VERSION ""

NS_ :

BS_:

BU_:

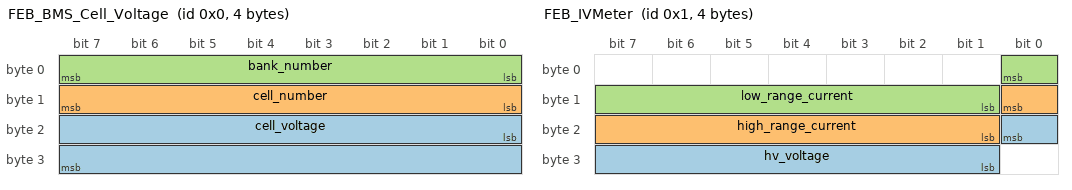
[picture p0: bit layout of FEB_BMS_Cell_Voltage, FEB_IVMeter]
BO_ 0 FEB_BMS_Cell_Voltage: 4 Vector__XXX
 SG_ cell_voltage : 16|16@1+ (0.001,0) [0|0] "mV" Vector__XXX
 SG_ cell_number : 8|8@1+ (1,0) [0|0] "" Vector__XXX
 SG_ bank_number : 0|8@1+ (1,0) [0|0] "" Vector__XXX

BO_ 1 FEB_IVMeter: 4 Vector__XXX
 SG_ hv_voltage : 16|8@0+ (1,0) [0|0] "V" Vector__XXX
 SG_ high_range_current : 8|8@0+ (1,0) [0|0] "" Vector__XXX
 SG_ low_range_current : 0|8@0+ (1,0) [0|0] "" Vector__XXX

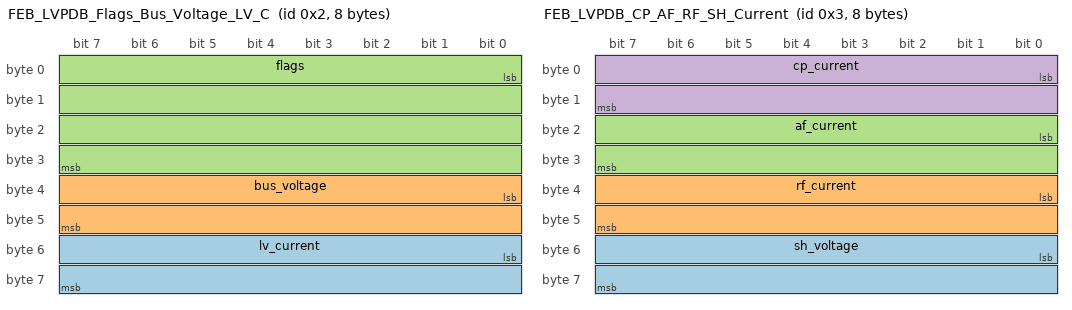
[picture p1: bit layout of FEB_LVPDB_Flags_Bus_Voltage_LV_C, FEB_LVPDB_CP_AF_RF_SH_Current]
BO_ 2 FEB_LVPDB_Flags_Bus_Voltage_LV_C: 8 Vector__XXX
 SG_ lv_current : 48|16@1+ (1,0) [0|0] "" Vector__XXX
 SG_ bus_voltage : 32|16@1+ (1,0) [0|0] "" Vector__XXX
 SG_ flags : 0|32@1+ (1,0) [0|0] "" Vector__XXX

BO_ 3 FEB_LVPDB_CP_AF_RF_SH_Current: 8 Vector__XXX
 SG_ sh_voltage : 48|16@1+ (1,0) [0|0] "" Vector__XXX
 SG_ rf_current : 32|16@1+ (1,0) [0|0] "" Vector__XXX
 SG_ af_current : 16|16@1+ (1,0) [0|0] "" Vector__XXX
 SG_ cp_current : 0|16@1+ (1,0) [0|0] "" Vector__XXX

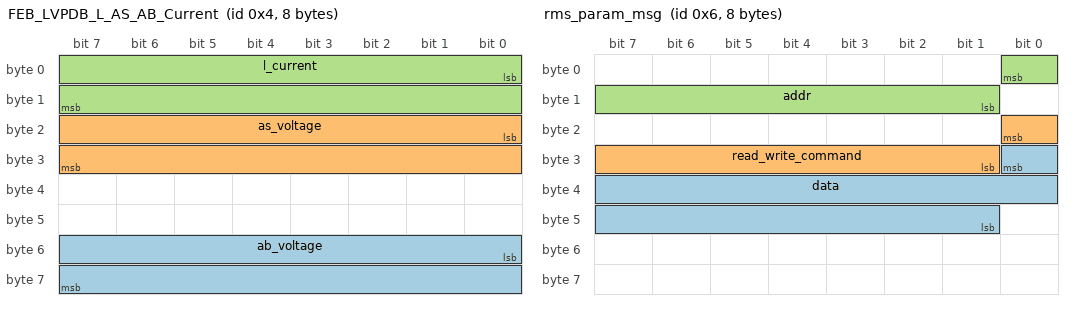
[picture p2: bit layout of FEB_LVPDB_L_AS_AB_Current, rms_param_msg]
BO_ 4 FEB_LVPDB_L_AS_AB_Current: 8 Vector__XXX
 SG_ ab_voltage : 48|16@1+ (1,0) [0|0] "" Vector__XXX
 SG_ as_voltage : 16|16@1+ (1,0) [0|0] "" Vector__XXX
 SG_ l_current : 0|16@1+ (1,0) [0|0] "" Vector__XXX

BO_ 5 normalized_brake: 5 Vector__XXX
 SG_ normalized_brake : 0|40@1+ (1,0) [0|0] "" Vector__XXX

BO_ 6 rms_param_msg: 8 Vector__XXX
 SG_ data : 24|16@0+ (1,0) [0|0] "" Vector__XXX
 SG_ read_write_command : 16|8@0+ (1,0) [0|0] "" Vector__XXX
 SG_ addr : 0|8@0+ (1,0) [0|0] "" Vector__XXX

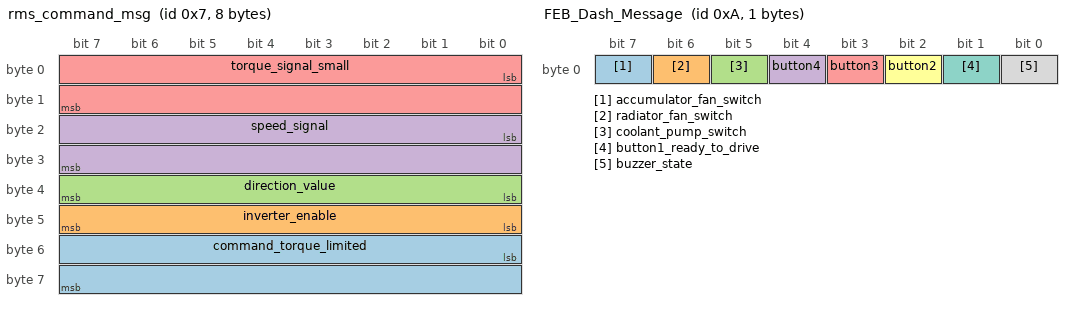
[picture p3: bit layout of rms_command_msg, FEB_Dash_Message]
BO_ 7 rms_command_msg: 8 Vector__XXX
 SG_ command_torque_limited : 48|16@1+ (1,0) [0|0] "" Vector__XXX
 SG_ inverter_enable : 40|8@1+ (1,0) [0|0] "" Vector__XXX
 SG_ direction_value : 32|8@1+ (1,0) [0|0] "" Vector__XXX
 SG_ speed_signal : 16|16@1+ (1,0) [0|0] "" Vector__XXX
 SG_ torque_signal_small : 0|16@1+ (1,0) [0|0] "" Vector__XXX

BO_ 8 bspd: 1 Vector__XXX
 SG_ bspd_state : 0|8@1+ (1,0) [0|0] "" Vector__XXX

BO_ 9 tps_current: 5 Vector__XXX
 SG_ current : 0|40@1+ (1,0) [0|0] "" Vector__XXX

BO_ 10 FEB_Dash_Message: 1 Vector__XXX
 SG_ accumulator_fan_switch : 7|1@1+ (1,0) [0|0] "" Vector__XXX
 SG_ radiator_fan_switch : 6|1@1+ (1,0) [0|0] "" Vector__XXX
 SG_ coolant_pump_switch : 5|1@1+ (1,0) [0|0] "" Vector__XXX
 SG_ button4 : 4|1@1+ (1,0) [0|0] "" Vector__XXX
 SG_ button3 : 3|1@1+ (1,0) [0|0] "" Vector__XXX
 SG_ button2 : 2|1@1+ (1,0) [0|0] "" Vector__XXX
 SG_ button1_ready_to_drive : 1|1@1+ (1,0) [0|0] "" Vector__XXX
 SG_ buzzer_state : 0|1@1+ (1,0) [0|0] "" Vector__XXX

BO_ 11 FEB_DART_TACH_measurements: 5 Vector__XXX
 SG_ fan5_speed : 32|8@1+ (1,0) [0|0] "" Vector__XXX
 SG_ fan4_speed : 24|8@1+ (1,0) [0|0] "" Vector__XXX
 SG_ fan3_speed : 16|8@1+ (1,0) [0|0] "" Vector__XXX
 SG_ fan2_speed : 8|8@1+ (1,0) [0|0] "" Vector__XXX
 SG_ fan1_speed : 0|8@1+ (1,0) [0|0] "" Vector__XXX

BO_ 12 FEB_PING_PONG_counter1: 8 Vector__XXX
 SG_ counter : 0|32@1- (1,0) [0|0] "" Vector__XXX

BO_ 13 FEB_PING_PONG_counter2: 8 Vector__XXX
 SG_ counter : 0|32@1- (1,0) [0|0] "" Vector__XXX

BO_ 14 FEB_PING_PONG_counter3: 8 Vector__XXX
 SG_ counter : 0|32@1- (1,0) [0|0] "" Vector__XXX

BO_ 15 FEB_PING_PONG_counter4: 8 Vector__XXX
 SG_ counter : 0|32@1- (1,0) [0|0] "" Vector__XXX

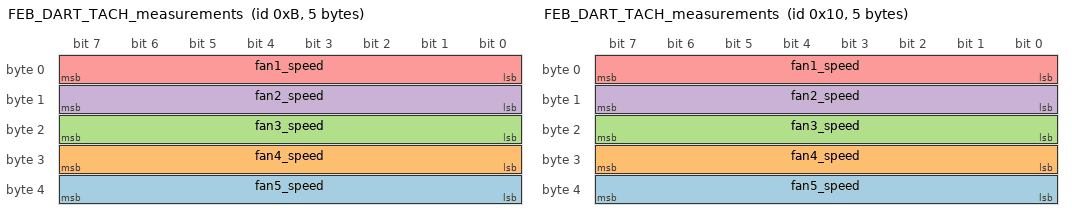
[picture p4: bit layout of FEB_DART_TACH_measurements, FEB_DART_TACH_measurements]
BO_ 16 FEB_DART_TACH_measurements: 5 Vector__XXX
 SG_ fan5_speed : 32|8@1+ (1,0) [0|0] "" Vector__XXX
 SG_ fan4_speed : 24|8@1+ (1,0) [0|0] "" Vector__XXX
 SG_ fan3_speed : 16|8@1+ (1,0) [0|0] "" Vector__XXX
 SG_ fan2_speed : 8|8@1+ (1,0) [0|0] "" Vector__XXX
 SG_ fan1_speed : 0|8@1+ (1,0) [0|0] "" Vector__XXX

CM_ BO_ 0 "BMS message for cell voltage.";
CM_ BO_ 1 "ivMeter message for low and high range current and HV voltage.";
CM_ BO_ 2 "LVPDB message for flags, bus voltage, LV current.";
CM_ BO_ 3 "LVPDB message for Coolant Pump Current, Accumulator Fans, Radiator Fans, Shutdown Source.";
CM_ BO_ 4 "LVPDB message for .";
CM_ BO_ 5 "PCU normalized brake message";
CM_ BO_ 6 "param_message.";
CM_ BO_ 7 "rms_command message.";
CM_ BO_ 8 "bspd message.";
CM_ BO_ 9 "tps current message.";
CM_ BO_ 10 "Dash message";
CM_ BO_ 11 "DART message for Tachometer measurements.";
CM_ BO_ 12 "PING PONG counter1.";
CM_ BO_ 13 "PING PONG counter2.";
CM_ BO_ 14 "PING PONG counter3.";
CM_ BO_ 15 "PING PONG counter4.";
CM_ BO_ 16 "DART message for Tachometer measurements.";
BA_DEF_ BO_  "SystemMessageLongSymbol" STRING ;
BA_DEF_DEF_  "SystemMessageLongSymbol" "";
BA_ "SystemMessageLongSymbol" BO_ 2 "FEB_LVPDB_Flags_Bus_Voltage_LV_Current";
